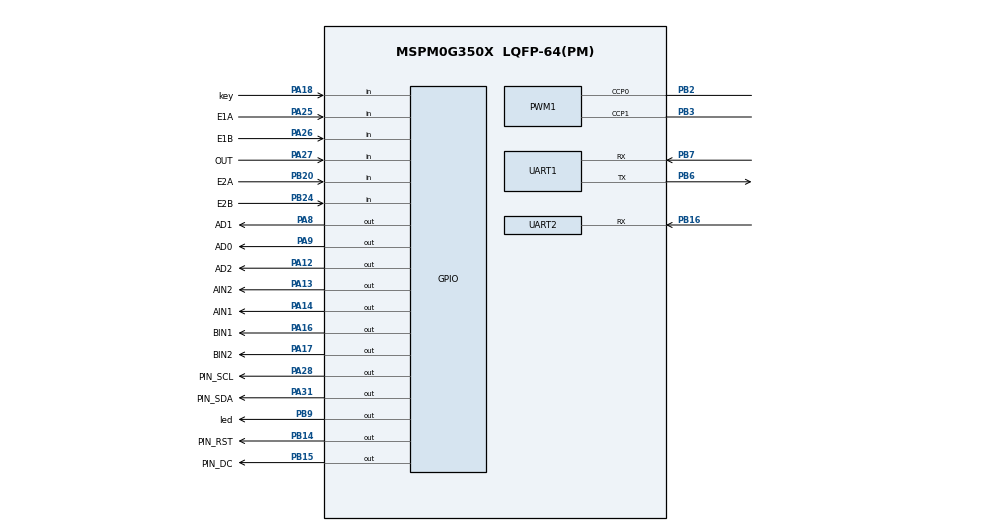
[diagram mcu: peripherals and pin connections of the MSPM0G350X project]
/**
 * @cliArgs --device "MSPM0G350X" --package "LQFP-64(PM)" --part "Default" --product "mspm0_sdk@2.01.00.03"
 * @versions {"tool":"1.20.0+3587"}
 */

/**
 * Import the modules used in this configuration.
 */
const GPIO    = scripting.addModule("/ti/driverlib/GPIO", {}, false);
const GPIO1   = GPIO.addInstance();
const GPIO2   = GPIO.addInstance();
const GPIO3   = GPIO.addInstance();
const GPIO4   = GPIO.addInstance();
const GPIO5   = GPIO.addInstance();
const GPIO6   = GPIO.addInstance();
const GPIO7   = GPIO.addInstance();
const GPIO8   = GPIO.addInstance();
const GPIO9   = GPIO.addInstance();
const GPIO10  = GPIO.addInstance();
const GPIO11  = GPIO.addInstance();
const GPIO12  = GPIO.addInstance();
const PWM     = scripting.addModule("/ti/driverlib/PWM", {}, false);
const PWM1    = PWM.addInstance();
const SYSCTL  = scripting.addModule("/ti/driverlib/SYSCTL");
const SYSTICK = scripting.addModule("/ti/driverlib/SYSTICK");
const TIMER   = scripting.addModule("/ti/driverlib/TIMER", {}, false);
const TIMER1  = TIMER.addInstance();
const UART    = scripting.addModule("/ti/driverlib/UART", {}, false);
const UART1   = UART.addInstance();
const UART2   = UART.addInstance();

/**
 * Write custom configuration values to the imported modules.
 */
const divider7       = system.clockTree["PLL_PDIV"];
divider7.divideValue = 2;

const divider9       = system.clockTree["UDIV"];
divider9.divideValue = 2;

const gate7  = system.clockTree["MFCLKGATE"];
gate7.enable = true;

const multiplier2         = system.clockTree["PLL_QDIV"];
multiplier2.multiplyValue = 5;

const mux8       = system.clockTree["HSCLKMUX"];
mux8.inputSelect = "HSCLKMUX_SYSPLL2X";

GPIO1.$name                              = "KEY";
GPIO1.associatedPins[0].$name            = "key";
GPIO1.associatedPins[0].direction        = "INPUT";
GPIO1.associatedPins[0].internalResistor = "PULL_UP";
GPIO1.associatedPins[0].pin.$assign      = "PA18";

const Board = scripting.addModule("/ti/driverlib/Board", {}, false);

GPIO2.$name                         = "LED";
GPIO2.associatedPins[0].$name       = "led";
GPIO2.associatedPins[0].pin.$assign = "PB9";

GPIO3.port                          = "PORTA";
GPIO3.$name                         = "BIN";
GPIO3.associatedPins.create(2);
GPIO3.associatedPins[0].$name       = "BIN1";
GPIO3.associatedPins[0].pin.$assign = "PA16";
GPIO3.associatedPins[1].$name       = "BIN2";
GPIO3.associatedPins[1].pin.$assign = "PA17";

GPIO4.port                          = "PORTA";
GPIO4.$name                         = "AIN";
GPIO4.associatedPins.create(2);
GPIO4.associatedPins[0].$name       = "AIN1";
GPIO4.associatedPins[0].pin.$assign = "PA14";
GPIO4.associatedPins[1].$name       = "AIN2";
GPIO4.associatedPins[1].pin.$assign = "PA13";

GPIO5.$name                               = "ENCODERA";
GPIO5.associatedPins.create(2);
GPIO5.associatedPins[0].$name             = "E1A";
GPIO5.associatedPins[0].direction         = "INPUT";
GPIO5.associatedPins[0].polarity          = "RISE";
GPIO5.associatedPins[0].interruptPriority = "0";
GPIO5.associatedPins[0].interruptEn       = true;
GPIO5.associatedPins[0].pin.$assign       = "PA25";
GPIO5.associatedPins[1].$name             = "E1B";
GPIO5.associatedPins[1].direction         = "INPUT";
GPIO5.associatedPins[1].polarity          = "RISE";
GPIO5.associatedPins[1].interruptPriority = "0";
GPIO5.associatedPins[1].interruptEn       = true;
GPIO5.associatedPins[1].pin.$assign       = "PA26";

GPIO6.$name                               = "ENCODERB";
GPIO6.associatedPins.create(2);
GPIO6.associatedPins[0].$name             = "E2A";
GPIO6.associatedPins[0].direction         = "INPUT";
GPIO6.associatedPins[0].polarity          = "RISE";
GPIO6.associatedPins[0].interruptPriority = "0";
GPIO6.associatedPins[0].interruptEn       = true;
GPIO6.associatedPins[0].pin.$assign       = "PB20";
GPIO6.associatedPins[1].$name             = "E2B";
GPIO6.associatedPins[1].direction         = "INPUT";
GPIO6.associatedPins[1].polarity          = "RISE";
GPIO6.associatedPins[1].interruptPriority = "0";
GPIO6.associatedPins[1].interruptEn       = true;
GPIO6.associatedPins[1].pin.$assign       = "PB24";

GPIO7.$name                         = "OLED_RST";
GPIO7.associatedPins[0].$name       = "PIN_RST";
GPIO7.associatedPins[0].pin.$assign = "PB14";

GPIO8.$name                         = "OLED_DC";
GPIO8.associatedPins[0].$name       = "PIN_DC";
GPIO8.associatedPins[0].pin.$assign = "PB15";

GPIO9.$name                         = "OLED_SCL";
GPIO9.associatedPins[0].$name       = "PIN_SCL";
GPIO9.associatedPins[0].pin.$assign = "PA28";

GPIO10.$name                         = "OLED_SDA";
GPIO10.associatedPins[0].$name       = "PIN_SDA";
GPIO10.associatedPins[0].pin.$assign = "PA31";

GPIO11.$name                         = "GS_AD";
GPIO11.port                          = "PORTA";
GPIO11.associatedPins.create(3);
GPIO11.associatedPins[0].$name       = "AD0";
GPIO11.associatedPins[0].pin.$assign = "PA9";
GPIO11.associatedPins[1].$name       = "AD1";
GPIO11.associatedPins[1].pin.$assign = "PA8";
GPIO11.associatedPins[2].$name       = "AD2";
GPIO11.associatedPins[2].pin.$assign = "PA12";

GPIO12.$name                         = "GS_OUT";
GPIO12.port                          = "PORTA";
GPIO12.associatedPins[0].$name       = "OUT";
GPIO12.associatedPins[0].direction   = "INPUT";
GPIO12.associatedPins[0].pin.$assign = "PA27";

PWM1.$name                      = "PWM_0";
PWM1.timerStartTimer            = true;
PWM1.pwmMode                    = "EDGE_ALIGN_UP";
PWM1.timerCount                 = 8000;
PWM1.peripheral.$assign         = "TIMA1";
PWM1.peripheral.ccp0Pin.$assign = "PB2";
PWM1.peripheral.ccp1Pin.$assign = "PB3";
PWM1.PWM_CHANNEL_0.$name        = "ti_driverlib_pwm_PWMTimerCC0";
PWM1.PWM_CHANNEL_1.$name        = "ti_driverlib_pwm_PWMTimerCC1";
PWM1.ccp0PinConfig.$name        = "ti_driverlib_gpio_GPIOPinGeneric4";
PWM1.ccp1PinConfig.$name        = "ti_driverlib_gpio_GPIOPinGeneric5";

SYSCTL.forceDefaultClkConfig = true;
SYSCTL.clockTreeEn           = true;

SYSTICK.periodEnable  = true;
SYSTICK.systickEnable = true;
SYSTICK.period        = 80000;

TIMER1.$name              = "TIMER_0";
TIMER1.timerClkPrescale   = 32;
TIMER1.timerMode          = "PERIODIC";
TIMER1.timerStartTimer    = true;
TIMER1.interrupts         = ["ZERO"];
TIMER1.timerPeriod        = "10 ms";
TIMER1.peripheral.$assign = "TIMG0";

UART1.$name                            = "UART_1";
UART1.enableFIFO                       = true;
UART1.rxFifoThreshold                  = "DL_UART_RX_FIFO_LEVEL_ONE_ENTRY";
UART1.enableDMARX                      = false;
UART1.enableDMATX                      = false;
UART1.enabledInterrupts                = ["RX"];
UART1.interruptPriority                = "1";
UART1.peripheral.$assign               = "UART1";
UART1.peripheral.rxPin.$assign         = "PB7";
UART1.peripheral.txPin.$assign         = "PB6";
UART1.txPinConfig.direction            = scripting.forceWrite("OUTPUT");
UART1.txPinConfig.hideOutputInversion  = scripting.forceWrite(false);
UART1.txPinConfig.onlyInternalResistor = scripting.forceWrite(false);
UART1.txPinConfig.passedPeripheralType = scripting.forceWrite("Digital");
UART1.txPinConfig.$name                = "ti_driverlib_gpio_GPIOPinGeneric11";
UART1.rxPinConfig.hideOutputInversion  = scripting.forceWrite(false);
UART1.rxPinConfig.onlyInternalResistor = scripting.forceWrite(false);
UART1.rxPinConfig.passedPeripheralType = scripting.forceWrite("Digital");
UART1.rxPinConfig.$name                = "ti_driverlib_gpio_GPIOPinGeneric12";

UART2.$name                             = "UART_2";
UART2.targetBaudRate                    = 115200;
UART2.enableFIFO                        = true;
UART2.rxFifoThreshold                   = "DL_UART_RX_FIFO_LEVEL_ONE_ENTRY";
UART2.enableInternalLoopback            = true;
UART2.enableDMARX                       = false;
UART2.enableDMATX                       = false;
UART2.enabledDMARXTriggers              = "DL_UART_DMA_INTERRUPT_RX";
UART2.peripheral.$assign                = "UART2";
UART2.peripheral.rxPin.$assign          = "PB16";
UART2.txPinConfig.direction             = scripting.forceWrite("OUTPUT");
UART2.txPinConfig.hideOutputInversion   = scripting.forceWrite(false);
UART2.txPinConfig.onlyInternalResistor  = scripting.forceWrite(false);
UART2.txPinConfig.passedPeripheralType  = scripting.forceWrite("Digital");
UART2.txPinConfig.$name                 = "ti_driverlib_gpio_GPIOPinGeneric13";
UART2.rxPinConfig.hideOutputInversion   = scripting.forceWrite(false);
UART2.rxPinConfig.onlyInternalResistor  = scripting.forceWrite(false);
UART2.rxPinConfig.passedPeripheralType  = scripting.forceWrite("Digital");
UART2.rxPinConfig.$name                 = "ti_driverlib_gpio_GPIOPinGeneric14";
UART2.DMA_CHANNEL_RX.$name              = "DMA_CH0";
UART2.DMA_CHANNEL_RX.addressMode        = "f2b";
UART2.DMA_CHANNEL_RX.srcLength          = "BYTE";
UART2.DMA_CHANNEL_RX.dstLength          = "BYTE";
UART2.DMA_CHANNEL_RX.destIncrement      = "INCREMENT";
UART2.DMA_CHANNEL_RX.transferSize       = 256;
UART2.DMA_CHANNEL_RX.peripheral.$assign = "DMA_CH0";

/**
 * Pinmux solution for unlocked pins/peripherals. This ensures that minor changes to the automatic solver in a future
 * version of the tool will not impact the pinmux you originally saw.  These lines can be completely deleted in order to
 * re-solve from scratch.
 */
Board.peripheral.$suggestSolution          = "DEBUGSS";
Board.peripheral.swclkPin.$suggestSolution = "PA20";
Board.peripheral.swdioPin.$suggestSolution = "PA19";
UART2.peripheral.txPin.$suggestSolution    = "PA21";
